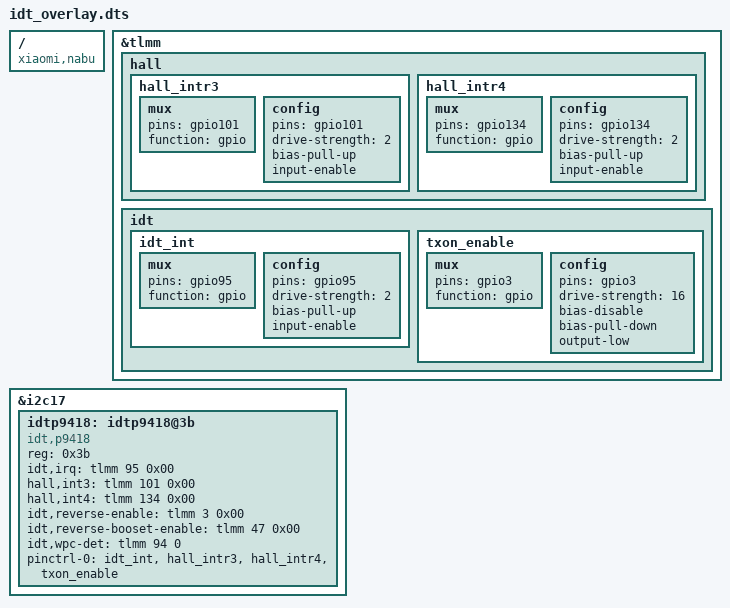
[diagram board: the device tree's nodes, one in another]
/dts-v1/;
/plugin/;

/ {
	compatible = "xiaomi,nabu", "qcom,sm8150";

    fragment@0 {
        target = <&tlmm>;
        __overlay__ {
            hall {
                hall_intr3: hall_intr3 {
                    mux {
                        pins = "gpio101";
                        function = "gpio";
                    };

                    config {
                        pins = "gpio101";
                        drive-strength = <2>;
                        bias-pull-up;
                        input-enable;
                    };
                };

                hall_intr4: hall_intr4 {
                    mux {
                        pins = "gpio134";
                        function = "gpio";
                    };

                    config {
                        pins = "gpio134";
                        drive-strength = <2>;
                        bias-pull-up;
                        input-enable;
                    };
                };
            };

            idt {
                idt_int: idt_int {
                    mux {
                        pins = "gpio95";
                        function = "gpio";
                    };

                    config {
                        pins = "gpio95";
                        drive-strength = <2>;
                        bias-pull-up;
                        input-enable;
                    };
                };

                txon_enable: txon_enable {
                    mux {
                        pins = "gpio3";
                        function = "gpio";
                    };

                    config {
                        pins = "gpio3";
                        drive-strength = <16>;
                        bias-disable;
                        bias-pull-down;
                        output-low;
                    };
                };
            };
        };
    };

    fragment@1 {
        target = <&i2c17>;
        __overlay__ {
            status = "okay";

            idtp9418: idtp9418@3b {
                compatible = "idt,p9418";
                reg = <0x3b>;
                status = "okay";
                idt,irq = <&tlmm 95 0x00>;
                hall,int3 = <&tlmm 101 0x00>;
                hall,int4 = <&tlmm 134 0x00>;
                idt,reverse-enable = <&tlmm 3 0x00>;
                idt,reverse-booset-enable = <&tlmm 47 0x00>;
                //                 idt,wpc-det = <&tlmm 94 GPIO_ACTIVE_HIGH>;
                idt,wpc-det = <&tlmm 94 0>;
                pinctrl-names = "idt_active", "idt_suspend";
                pinctrl-0 = <&idt_int &hall_intr3 &hall_intr4 &txon_enable>;
            };
        };
    };
};
